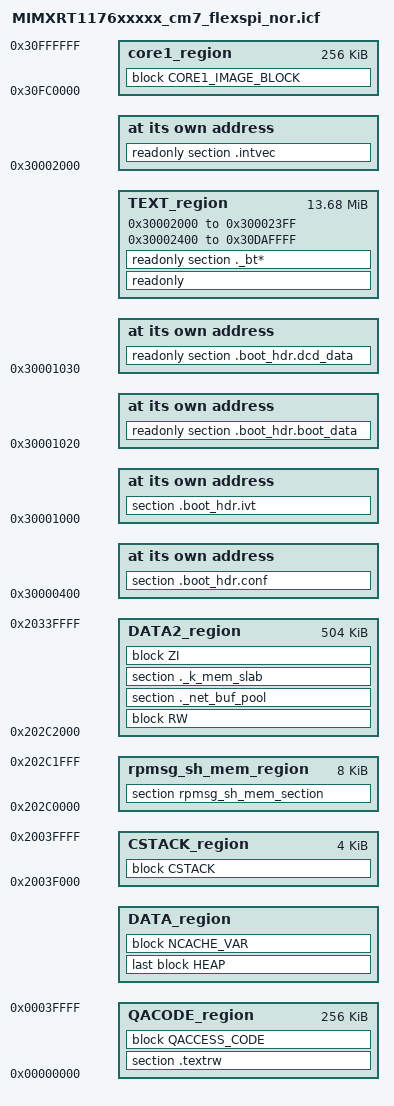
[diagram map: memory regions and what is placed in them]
/*
** ###################################################################
**     Processors:          MIMXRT1176AVM8A_cm7
**                          MIMXRT1176CVM8A_cm7
**                          MIMXRT1176DVMAA_cm7
**
**     Compiler:            IAR ANSI C/C++ Compiler for ARM
**     Reference manual:    IMXRT1170RM, Rev 0, 12/2020
**     Version:             rev. 1.0, 2020-12-29
**     Build:               b210226
**
**     Abstract:
**         Linker file for the IAR ANSI C/C++ Compiler for ARM
**
**     Copyright 2016 Freescale Semiconductor, Inc.
**     Copyright 2016-2021 NXP
**     All rights reserved.
**
**     SPDX-License-Identifier: BSD-3-Clause
**
**     http:                 www.nxp.com
**     mail:                 support@nxp.com
**
** ###################################################################
*/
/* NVM */
/* By default, the NVM is not used. */
if (!isdefinedsymbol(gUseNVMLink_d)) {
    define symbol gUseNVMLink_d = 0;
}

if (!isdefinedsymbol(gEraseNVMLink_d)) {
    define symbol gEraseNVMLink_d = 0;
}

if (!isdefinedsymbol(gNVMSectorCountLink_d)) {
    define symbol gNVMSectorCountLink_d = 4;
}
/* NVM */
/* flash layout */

define symbol __ram_vector_table_size__        =  isdefinedsymbol(__ram_vector_table__) ? 0x00000400 : 0;
define symbol __ram_vector_table_offset__      =  isdefinedsymbol(__ram_vector_table__) ? 0x000003FF : 0;

define symbol m_interrupts_start       = 0x30002000;
define symbol m_interrupts_end         = 0x300023FF;

define symbol m_text_start             = 0x30002400;
define symbol _ROM_END_                = 0x30DBFFFF;


/* NOTE: Flash in range 0x30DBFFFF - 0x30FBFFFF is reserved for litteFS data */

/*define symbol m_text_end               = 0x30FBFFFF;*/

define symbol m_interrupts_ram_start   = 0x20000000;
define symbol m_interrupts_ram_end     = 0x20000000 + __ram_vector_table_offset__;

define symbol m_data_start             = m_interrupts_ram_start + __ram_vector_table_size__;
define symbol m_data_end               = 0x2003FFFF;

if (isdefinedsymbol(__use_shmem__)) {
  define exported symbol rpmsg_sh_mem_start      = 0x202C0000;
  define exported symbol rpmsg_sh_mem_end        = 0x202C1FFF;

  define symbol m_data2_start                    = 0x202C2000;
  define symbol m_data2_end                      = 0x2033FFFF;

  define exported symbol __NCACHE_REGION_START   = rpmsg_sh_mem_start;
  define exported symbol __NCACHE_REGION_SIZE    = rpmsg_sh_mem_end - rpmsg_sh_mem_start + 1;
} else {
  define symbol m_data2_start                    = 0x202C0000;
  define symbol m_data2_end                      = 0x2033FFFF;

  define exported symbol __NCACHE_REGION_START   = m_data2_start;
  define exported symbol __NCACHE_REGION_SIZE    = 0x0;
}

define symbol m_qacode_start           = 0x00000000;
define symbol m_qacode_end             = 0x0003FFFF;

define exported symbol m_boot_hdr_conf_start = 0x30000400;
define symbol m_boot_hdr_ivt_start           = 0x30001000;
define symbol m_boot_hdr_boot_data_start     = 0x30001020;
define symbol m_boot_hdr_dcd_data_start      = 0x30001030;

define exported symbol core1_image_start     = 0x30FC0000;
define exported symbol core1_image_end       = 0x30FFFFFF;
define symbol STORAGE_AREA_LENGTH  = 0x10000;

define symbol STORAGE_AREA_SIZE  = STORAGE_AREA_LENGTH;
define symbol STORAGE_AREA_START = _ROM_END_ - STORAGE_AREA_SIZE + 1;
define symbol m_text_end         = STORAGE_AREA_START -1;
/*** NVM Configuration Start ***/
if (isdefinedsymbol(gUseNVMLink_d))
{
  define exported symbol NVM_AREA_START = STORAGE_AREA_START;
  
  define exported symbol NV_STORAGE_SECTOR_SIZE = 0x1000;  /* 4k flash sector size */
  define exported symbol NV_STORAGE_MAX_SECTORS = gNVMSectorCountLink_d;
  define exported symbol NVM_AREA_SIZE = NV_STORAGE_SECTOR_SIZE * NV_STORAGE_MAX_SECTORS;
  if (NVM_AREA_SIZE > STORAGE_AREA_SIZE)
  {
    error "Required NVM storage area is biger than STORAGE_AREA_SIZE";
  }
  define exported symbol NV_STORAGE_END_ADDRESS = NVM_AREA_START + NVM_AREA_SIZE - 1;
  define exported symbol NV_STORAGE_START_ADDRESS = NVM_AREA_START;
}
/*** NVM Configuration End ***/

/*** littleFS configuration Start ***/
define exported symbol EDGEFAST_BT_LITTLEFS_STORAGE_START_ADDRESS = _ROM_END_ + 1;
define exported symbol EDGEFAST_BT_LITTLEFS_STORAGE_SECTOR_SIZE = 0x1000;  /* 4k flash sector size */
define exported symbol EDGEFAST_BT_LITTLEFS_STORAGE_MAX_SECTORS = (0x30FBFFFF - EDGEFAST_BT_LITTLEFS_STORAGE_START_ADDRESS) / EDGEFAST_BT_LITTLEFS_STORAGE_SECTOR_SIZE;
/*** littleFS configuration End ***/

/* Sizes */
if (isdefinedsymbol(__stack_size__)) {
  define symbol __size_cstack__        = __stack_size__;
} else {
  define symbol __size_cstack__        = 0x1000;
}

if (isdefinedsymbol(__heap_size__)) {
  define symbol __size_heap__          = __heap_size__;
} else {
  define symbol __size_heap__          = 0x400;
}

define exported symbol __VECTOR_TABLE          = m_interrupts_start;
define exported symbol __VECTOR_RAM            = isdefinedsymbol(__ram_vector_table__) ? m_interrupts_ram_start : m_interrupts_start;
define exported symbol __RAM_VECTOR_TABLE_SIZE = __ram_vector_table_size__;

define memory mem with size = 4G;
define region TEXT_region = mem:[from m_interrupts_start to m_interrupts_end]
                          | mem:[from m_text_start to m_text_end];
define region QACODE_region = mem:[from m_qacode_start to m_qacode_end];
define region DATA_region = mem:[from m_data_start to m_data_end-__size_cstack__];
define region DATA2_region = mem:[from m_data2_start to m_data2_end];
define region CSTACK_region = mem:[from m_data_end-__size_cstack__+1 to m_data_end];
if (isdefinedsymbol(__use_shmem__)) {
  define region rpmsg_sh_mem_region     = mem:[from rpmsg_sh_mem_start to rpmsg_sh_mem_end];
}

define block CSTACK    with alignment = 8, size = __size_cstack__   { };
define block HEAP      with alignment = 8, size = __size_heap__     { };
define block RW        { readwrite };
define block ZI        { zi };
define block NCACHE_VAR    { section NonCacheable , section NonCacheable.init };

define block QACCESS_CODE  { section CodeQuickAccess };

define region core1_region = mem:[from core1_image_start to core1_image_end];
define block CORE1_IMAGE_BLOCK          { section  __core1_image };

initialize by copy { readwrite, section .textrw, section CodeQuickAccess,
  object fsl_adapter_flexspi_nor_flash.o,
  object NV_Flash.o,
  object mflash_drv.o,
  object fsl_flexspi.o,

 };
do not initialize  { section .noinit };
if (isdefinedsymbol(__use_shmem__)) {
  do not initialize  { section rpmsg_sh_mem_section };
}

place at address mem: m_interrupts_start    { readonly section .intvec };

place at address mem:m_boot_hdr_conf_start { section .boot_hdr.conf };
place at address mem:m_boot_hdr_ivt_start { section .boot_hdr.ivt };
place at address mem:m_boot_hdr_boot_data_start { readonly section .boot_hdr.boot_data };
place at address mem:m_boot_hdr_dcd_data_start { readonly section .boot_hdr.dcd_data };

keep{ section .boot_hdr.conf, section .boot_hdr.ivt, section .boot_hdr.boot_data, section .boot_hdr.dcd_data,section NVM_ADAPTER_TABLE };
keep { section .flash_area_list, section ._net_buf_pool, section ._k_mem_slab, section ._bt*, section ._settings* };

place in TEXT_region                        { readonly,readonly section ._bt* };
place in DATA2_region                        { block RW,section ._net_buf_pool, section ._k_mem_slab };
place in DATA2_region                        { block ZI };
place in DATA_region                        { last block HEAP };
place in DATA_region                        { block NCACHE_VAR };
place in CSTACK_region                      { block CSTACK };
place in QACODE_region                      { section .textrw};
place in QACODE_region                      { block QACCESS_CODE };
if (isdefinedsymbol(__use_shmem__)) {
  place in rpmsg_sh_mem_region                { section rpmsg_sh_mem_section };
}
place in core1_region                       { block CORE1_IMAGE_BLOCK };
